VERSION ""

NS_ :

BS_:

BU_: HANDCART HANDCART BMS_HV BMS_HV HANDCART CELLBOARD BMS_HV MAINBOARD HANDCART BMS_HV HANDCART BMS_HV CELLBOARD HANDCART BMS_HV CELLBOARD HANDCART BMS_HV MAINBOARD HANDCART MAINBOARD BMS_HV CELLBOARD HANDCART MAINBOARD BMS_HV CELLBOARD HANDCART MAINBOARD BMS_HV MAINBOARD MAINBOARD HANDCART CELLBOARD BMS_HV MAINBOARD CELLBOARD HANDCART CELLBOARD BMS_HV

BO_ 1537 BOARD_STATUS: 4 Vector__XXX
 SG_ balancing_cells_CELL17 : 30|1@1+ (1,0) [0|1] "" Vector__XXX
 SG_ balancing_cells_CELL16 : 29|1@1+ (1,0) [0|1] "" Vector__XXX
 SG_ balancing_cells_CELL15 : 28|1@1+ (1,0) [0|1] "" Vector__XXX
 SG_ balancing_cells_CELL14 : 27|1@1+ (1,0) [0|1] "" Vector__XXX
 SG_ balancing_cells_CELL13 : 26|1@1+ (1,0) [0|1] "" Vector__XXX
 SG_ balancing_cells_CELL12 : 25|1@1+ (1,0) [0|1] "" Vector__XXX
 SG_ balancing_cells_CELL11 : 24|1@1+ (1,0) [0|1] "" Vector__XXX
 SG_ balancing_cells_CELL10 : 23|1@1+ (1,0) [0|1] "" Vector__XXX
 SG_ balancing_cells_CELL9 : 22|1@1+ (1,0) [0|1] "" Vector__XXX
 SG_ balancing_cells_CELL8 : 21|1@1+ (1,0) [0|1] "" Vector__XXX
 SG_ balancing_cells_CELL7 : 20|1@1+ (1,0) [0|1] "" Vector__XXX
 SG_ balancing_cells_CELL6 : 19|1@1+ (1,0) [0|1] "" Vector__XXX
 SG_ balancing_cells_CELL5 : 18|1@1+ (1,0) [0|1] "" Vector__XXX
 SG_ balancing_cells_CELL4 : 17|1@1+ (1,0) [0|1] "" Vector__XXX
 SG_ balancing_cells_CELL3 : 16|1@1+ (1,0) [0|1] "" Vector__XXX
 SG_ balancing_cells_CELL2 : 15|1@1+ (1,0) [0|1] "" Vector__XXX
 SG_ balancing_cells_CELL1 : 14|1@1+ (1,0) [0|1] "" Vector__XXX
 SG_ balancing_cells_CELL0 : 13|1@1+ (1,0) [0|1] "" Vector__XXX
 SG_ balancing_status : 12|1@1+ (1,0) [0|1] "" Vector__XXX
 SG_ errors_OPEN_WIRE : 11|1@1+ (1,0) [0|1] "" Vector__XXX
 SG_ errors_TEMP_COMM_5 : 10|1@1+ (1,0) [0|1] "" Vector__XXX
 SG_ errors_TEMP_COMM_4 : 9|1@1+ (1,0) [0|1] "" Vector__XXX
 SG_ errors_TEMP_COMM_3 : 8|1@1+ (1,0) [0|1] "" Vector__XXX
 SG_ errors_TEMP_COMM_2 : 7|1@1+ (1,0) [0|1] "" Vector__XXX
 SG_ errors_TEMP_COMM_1 : 6|1@1+ (1,0) [0|1] "" Vector__XXX
 SG_ errors_TEMP_COMM_0 : 5|1@1+ (1,0) [0|1] "" Vector__XXX
 SG_ errors_LTC_COMM : 4|1@1+ (1,0) [0|1] "" Vector__XXX
 SG_ errors_CAN_COMM : 3|1@1+ (1,0) [0|1] "" Vector__XXX
 SG_ cellboard_id : 0|3@1+ (1,0) [0|7] "" Vector__XXX

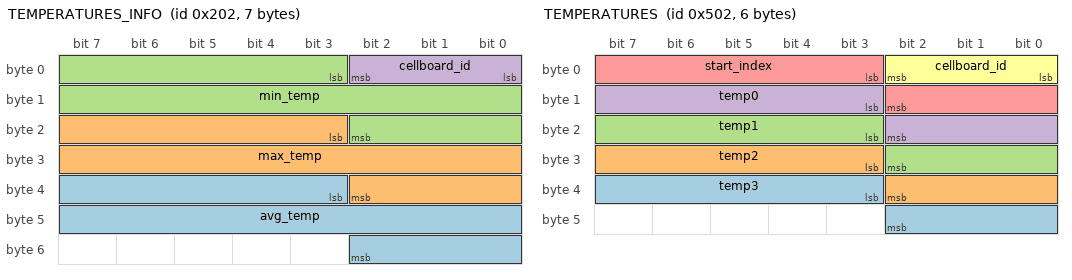
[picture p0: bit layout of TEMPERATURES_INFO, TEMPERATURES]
BO_ 514 TEMPERATURES_INFO: 7 Vector__XXX
 SG_ avg_temp : 35|16@1+ (0.0015259021896696422,-20) [-20|80] "" Vector__XXX
 SG_ max_temp : 19|16@1+ (0.0015259021896696422,-20) [-20|80] "" Vector__XXX
 SG_ min_temp : 3|16@1+ (0.0015259021896696422,-20) [-20|80] "" Vector__XXX
 SG_ cellboard_id : 0|3@1+ (1,0) [0|7] "" Vector__XXX

BO_ 1282 TEMPERATURES: 6 Vector__XXX
 SG_ temp3 : 35|8@1+ (0.39215686274509803,-20) [-20|80] "" Vector__XXX
 SG_ temp2 : 27|8@1+ (0.39215686274509803,-20) [-20|80] "" Vector__XXX
 SG_ temp1 : 19|8@1+ (0.39215686274509803,-20) [-20|80] "" Vector__XXX
 SG_ temp0 : 11|8@1+ (0.39215686274509803,-20) [-20|80] "" Vector__XXX
 SG_ start_index : 3|8@1+ (1,0) [0|255] "" Vector__XXX
 SG_ cellboard_id : 0|3@1+ (1,0) [0|7] "" Vector__XXX

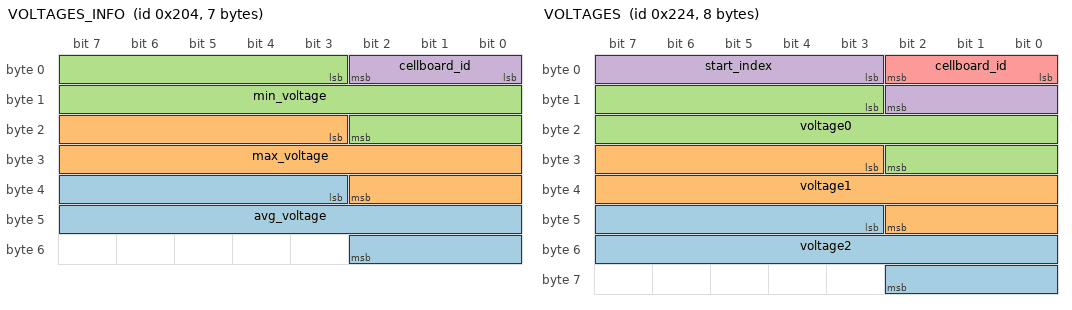
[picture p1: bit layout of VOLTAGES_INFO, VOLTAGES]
BO_ 516 VOLTAGES_INFO: 7 Vector__XXX
 SG_ avg_voltage : 35|16@1+ (7.629510948348211e-05,0) [0|5] "" Vector__XXX
 SG_ max_voltage : 19|16@1+ (7.629510948348211e-05,0) [0|5] "" Vector__XXX
 SG_ min_voltage : 3|16@1+ (7.629510948348211e-05,0) [0|5] "" Vector__XXX
 SG_ cellboard_id : 0|3@1+ (1,0) [0|7] "" Vector__XXX

BO_ 548 VOLTAGES: 8 Vector__XXX
 SG_ voltage2 : 43|16@1+ (7.629510948348211e-05,0) [0|5] "" Vector__XXX
 SG_ voltage1 : 27|16@1+ (7.629510948348211e-05,0) [0|5] "" Vector__XXX
 SG_ voltage0 : 11|16@1+ (7.629510948348211e-05,0) [0|5] "" Vector__XXX
 SG_ start_index : 3|8@1+ (1,0) [0|255] "" Vector__XXX
 SG_ cellboard_id : 0|3@1+ (1,0) [0|7] "" Vector__XXX

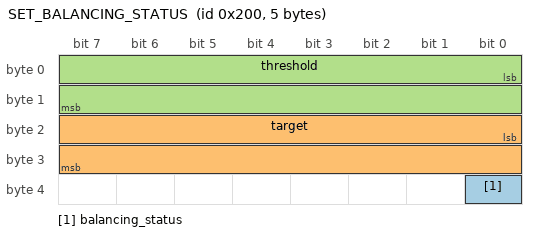
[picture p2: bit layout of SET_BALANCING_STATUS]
BO_ 512 SET_BALANCING_STATUS: 5 Vector__XXX
 SG_ balancing_status : 32|1@1+ (1,0) [0|1] "" Vector__XXX
 SG_ target : 16|16@1+ (1,0) [0|65535] "" Vector__XXX
 SG_ threshold : 0|16@1+ (1,0) [0|65535] "" Vector__XXX

BO_ 0 JMP_TO_BLT: 2 Vector__XXX
 SG_ board_index : 3|8@1+ (1,0) [0|255] "" Vector__XXX
 SG_ cellboard_id : 0|3@1+ (1,0) [0|7] "" Vector__XXX

BO_ 4 FLASH_CELLBOARD_0_TX: 0 Vector__XXX

BO_ 5 FLASH_CELLBOARD_0_RX: 0 Vector__XXX

BO_ 6 FLASH_CELLBOARD_1_TX: 0 Vector__XXX

BO_ 7 FLASH_CELLBOARD_1_RX: 0 Vector__XXX

BO_ 8 FLASH_CELLBOARD_2_TX: 0 Vector__XXX

BO_ 9 FLASH_CELLBOARD_2_RX: 0 Vector__XXX

BO_ 10 FLASH_CELLBOARD_3_TX: 0 Vector__XXX

BO_ 11 FLASH_CELLBOARD_3_RX: 0 Vector__XXX

BO_ 12 FLASH_CELLBOARD_4_TX: 0 Vector__XXX

BO_ 13 FLASH_CELLBOARD_4_RX: 0 Vector__XXX

BO_ 14 FLASH_CELLBOARD_5_TX: 0 Vector__XXX

BO_ 15 FLASH_CELLBOARD_5_RX: 0 Vector__XXX

BO_ 259 CELLBOARD_VERSION: 9 Vector__XXX
 SG_ canlib_build_time : 35|32@1+ (1,0) [0|4294967295] "" Vector__XXX
 SG_ component_build_hash : 3|32@1+ (1,0) [0|4294967295] "" Vector__XXX
 SG_ cellboard_id : 0|3@1+ (1,0) [0|7] "" Vector__XXX

CM_ BO_ 1537 "Cellboard's status";
CM_ BO_ 514 "Cellboard temperature precalculated values";
CM_ BO_ 1282 "Cells' temperatures";
CM_ BO_ 516 "Cellboard voltages precalculated values";
CM_ BO_ 548 "Cells' voltages";
CM_ BO_ 512 "Set balancing status for cells";
CM_ BO_ 0 "Starts firmware update";
CM_ BO_ 259 "Periodic message containing current can definition version";
BA_DEF_ BO_  "GenMsgCycleTime" INT 0 65535;
BA_DEF_DEF_  "GenMsgCycleTime" 0;
BA_ "GenMsgCycleTime" BO_ 259 1000;
VAL_ 1537 balancing_status 0 "OFF" 1 "DISCHARGE" ;
VAL_ 1537 cellboard_id 0 "CELLBOARD_0" 1 "CELLBOARD_1" 2 "CELLBOARD_2" 3 "CELLBOARD_3" 4 "CELLBOARD_4" 5 "CELLBOARD_5" ;
VAL_ 514 cellboard_id 0 "CELLBOARD_0" 1 "CELLBOARD_1" 2 "CELLBOARD_2" 3 "CELLBOARD_3" 4 "CELLBOARD_4" 5 "CELLBOARD_5" ;
VAL_ 1282 cellboard_id 0 "CELLBOARD_0" 1 "CELLBOARD_1" 2 "CELLBOARD_2" 3 "CELLBOARD_3" 4 "CELLBOARD_4" 5 "CELLBOARD_5" ;
VAL_ 516 cellboard_id 0 "CELLBOARD_0" 1 "CELLBOARD_1" 2 "CELLBOARD_2" 3 "CELLBOARD_3" 4 "CELLBOARD_4" 5 "CELLBOARD_5" ;
VAL_ 548 cellboard_id 0 "CELLBOARD_0" 1 "CELLBOARD_1" 2 "CELLBOARD_2" 3 "CELLBOARD_3" 4 "CELLBOARD_4" 5 "CELLBOARD_5" ;
VAL_ 512 balancing_status 0 "OFF" 1 "DISCHARGE" ;
VAL_ 0 cellboard_id 0 "CELLBOARD_0" 1 "CELLBOARD_1" 2 "CELLBOARD_2" 3 "CELLBOARD_3" 4 "CELLBOARD_4" 5 "CELLBOARD_5" ;
VAL_ 259 cellboard_id 0 "CELLBOARD_0" 1 "CELLBOARD_1" 2 "CELLBOARD_2" 3 "CELLBOARD_3" 4 "CELLBOARD_4" 5 "CELLBOARD_5" ;
